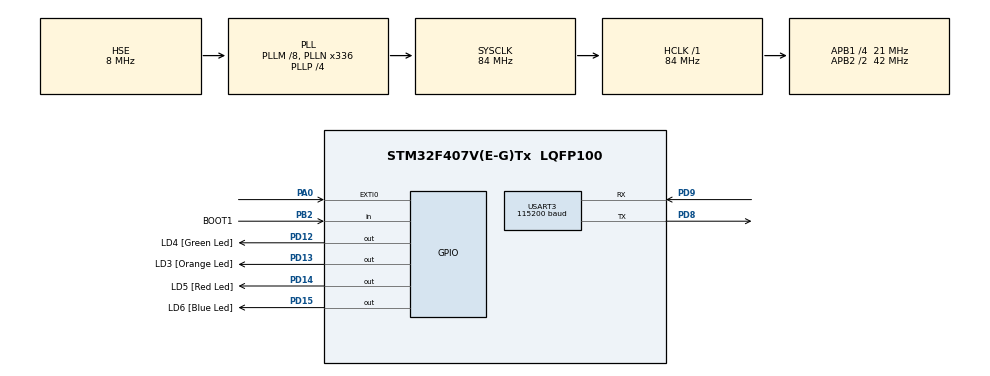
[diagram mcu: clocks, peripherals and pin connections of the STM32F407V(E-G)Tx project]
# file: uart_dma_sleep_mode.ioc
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Dma.Request0=USART3_RX
Dma.Request1=USART3_TX
Dma.USART3_RX.0.Direction=DMA_PERIPH_TO_MEMORY
Dma.USART3_RX.0.FIFOMode=DMA_FIFOMODE_DISABLE
Dma.USART3_RX.0.Instance=DMA1_Stream1
Dma.USART3_RX.0.MemDataAlignment=DMA_MDATAALIGN_BYTE
Dma.USART3_RX.0.MemInc=DMA_MINC_ENABLE
Dma.USART3_RX.0.Mode=DMA_NORMAL
Dma.USART3_RX.0.PeriphDataAlignment=DMA_PDATAALIGN_BYTE
Dma.USART3_RX.0.PeriphInc=DMA_PINC_DISABLE
Dma.USART3_RX.0.Priority=DMA_PRIORITY_LOW
Dma.USART3_TX.1.Direction=DMA_MEMORY_TO_PERIPH
Dma.USART3_TX.1.FIFOMode=DMA_FIFOMODE_ENABLE
Dma.USART3_TX.1.FIFOThreshold=DMA_FIFO_THRESHOLD_FULL
Dma.USART3_TX.1.Instance=DMA1_Stream3
Dma.USART3_TX.1.MemBurst=DMA_MBURST_SINGLE
Dma.USART3_TX.1.MemDataAlignment=DMA_MDATAALIGN_BYTE
Dma.USART3_TX.1.MemInc=DMA_MINC_ENABLE
Dma.USART3_TX.1.Mode=DMA_NORMAL
Dma.USART3_TX.1.PeriphBurst=DMA_PBURST_SINGLE
Dma.USART3_TX.1.PeriphDataAlignment=DMA_PDATAALIGN_BYTE
Dma.USART3_TX.1.PeriphInc=DMA_PINC_DISABLE
Dma.USART3_TX.1.Priority=DMA_PRIORITY_LOW
Mcu.Family=STM32F4
Mcu.Name=STM32F407V(E-G)Tx
Mcu.Package=LQFP100
NVIC.DMA1_Stream1_IRQn=true\:0\:0\:false\:false\:true\:false\:true
NVIC.DMA1_Stream3_IRQn=true\:0\:0\:false\:false\:true\:false\:true
NVIC.EXTI0_IRQn=true\:0\:0\:false\:false\:true\:true\:true
NVIC.PriorityGroup=NVIC_PRIORITYGROUP_0
PA0-WKUP.Signal=GPXTI0
PA13.GPIO_Label=SWDIO
PA13.Mode=Serial_Wire
PA13.Signal=SYS_JTMS-SWDIO
PA14.GPIO_Label=SWCLK
PA14.Mode=Serial_Wire
PA14.Signal=SYS_JTCK-SWCLK
PB2.GPIO_Label=BOOT1
PB2.GPIO_Mode=GPIO_MODE_INPUT
PB2.GPIO_PuPd=GPIO_NOPULL
PB2.Signal=GPIO_Input
PB3.GPIO_Label=SWO
PB3.Signal=SYS_JTDO-SWO
PC14-OSC32_IN.GPIO_Label=PC14-OSC32_IN
PC14-OSC32_IN.Mode=LSE-External-Oscillator
PC14-OSC32_IN.Signal=RCC_OSC32_IN
PC15-OSC32_OUT.GPIO_Label=PC15-OSC32_OUT
PC15-OSC32_OUT.Mode=LSE-External-Oscillator
PC15-OSC32_OUT.Signal=RCC_OSC32_OUT
PD12.GPIO_Label=LD4 [Green Led]
PD12.GPIO_PuPd=GPIO_NOPULL
PD12.GPIO_Speed=GPIO_SPEED_FREQ_LOW
PD12.Signal=GPIO_Output
PD13.GPIO_Label=LD3 [Orange Led]
PD13.GPIO_PuPd=GPIO_NOPULL
PD13.GPIO_Speed=GPIO_SPEED_FREQ_LOW
PD13.Signal=GPIO_Output
PD14.GPIO_Label=LD5 [Red Led]
PD14.GPIO_PuPd=GPIO_NOPULL
PD14.GPIO_Speed=GPIO_SPEED_FREQ_LOW
PD14.Signal=GPIO_Output
PD15.GPIO_Label=LD6 [Blue Led]
PD15.GPIO_PuPd=GPIO_NOPULL
PD15.GPIO_Speed=GPIO_SPEED_FREQ_LOW
PD15.Signal=GPIO_Output
PD8.Mode=Asynchronous
PD8.Signal=USART3_TX
PD9.Mode=Asynchronous
PD9.Signal=USART3_RX
PH0-OSC_IN.GPIO_Label=PH0-OSC_IN
PH0-OSC_IN.Mode=HSE-External-Oscillator
PH0-OSC_IN.Signal=RCC_OSC_IN
PH1-OSC_OUT.GPIO_Label=PH1-OSC_OUT
PH1-OSC_OUT.Mode=HSE-External-Oscillator
PH1-OSC_OUT.Signal=RCC_OSC_OUT
ProjectManager.HeapSize=0x200
ProjectManager.StackSize=0x400
ProjectManager.TargetToolchain=STM32CubeIDE
RCC.48MHZClocksFreq_Value=48000000
RCC.AHBFreq_Value=84000000
RCC.APB1CLKDivider=RCC_HCLK_DIV4
RCC.APB1Freq_Value=21000000
RCC.APB1TimFreq_Value=42000000
RCC.APB2CLKDivider=RCC_HCLK_DIV2
RCC.APB2Freq_Value=42000000
RCC.APB2TimFreq_Value=84000000
RCC.CortexFreq_Value=84000000
RCC.HCLKFreq_Value=84000000
RCC.HSE_VALUE=8000000
RCC.HSI_VALUE=16000000
RCC.PLLM=8
RCC.PLLN=336
RCC.PLLP=RCC_PLLP_DIV4
RCC.PLLQ=7
RCC.PLLSourceVirtual=RCC_PLLSOURCE_HSE
RCC.SYSCLKFreq_VALUE=84000000
RCC.SYSCLKSource=RCC_SYSCLKSOURCE_PLLCLK
RCC.VCOOutputFreq_Value=336000000
USART3.BaudRate=115200
USART3.VirtualMode=VM_ASYNC
board=STM32F407G-DISC1

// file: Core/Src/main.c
/* USER CODE BEGIN Header */
/**
  ******************************************************************************
  * @file           : main.c
  * @brief          : Main program body
  ******************************************************************************
  * @attention
  *
  * <h2><center>&copy; Copyright (c) 2020 STMicroelectronics.
  * All rights reserved.</center></h2>
  *
  * This software component is licensed by ST under Ultimate Liberty license
  * SLA0044, the "License"; You may not use this file except in compliance with
  * the License. You may obtain a copy of the License at:
  *                             www.st.com/SLA0044
  *
  ******************************************************************************
  */
/* USER CODE END Header */
#include "main.h"

UART_HandleTypeDef huart3;
DMA_HandleTypeDef hdma_usart3_rx;
DMA_HandleTypeDef hdma_usart3_tx;

void SystemClock_Config(void);
static void MX_GPIO_Init(void);
static void MX_DMA_Init(void);
static void MX_USART3_UART_Init(void);

int main(void)
{

  /* MCU Configuration--------------------------------------------------------*/

  /* Reset of all peripherals, Initializes the Flash interface and the Systick. */
  HAL_Init();

  /* Configure the system clock */
  SystemClock_Config();

  /* Initialize all configured peripherals */
  MX_GPIO_Init();
  MX_DMA_Init();
  MX_USART3_UART_Init();

  /* Infinite loop */
  while (1)
  {

  }
}

void SystemClock_Config(void)
{
  RCC_OscInitTypeDef RCC_OscInitStruct = {0};
  RCC_ClkInitTypeDef RCC_ClkInitStruct = {0};

  /** Configure the main internal regulator output voltage
  */
  __HAL_RCC_PWR_CLK_ENABLE();
  __HAL_PWR_VOLTAGESCALING_CONFIG(PWR_REGULATOR_VOLTAGE_SCALE1);
  /** Initializes the RCC Oscillators according to the specified parameters
  * in the RCC_OscInitTypeDef structure.
  */
  RCC_OscInitStruct.OscillatorType = RCC_OSCILLATORTYPE_HSE;
  RCC_OscInitStruct.HSEState = RCC_HSE_ON;
  RCC_OscInitStruct.PLL.PLLState = RCC_PLL_ON;
  RCC_OscInitStruct.PLL.PLLSource = RCC_PLLSOURCE_HSE;
  RCC_OscInitStruct.PLL.PLLM = 8;
  RCC_OscInitStruct.PLL.PLLN = 336;
  RCC_OscInitStruct.PLL.PLLP = RCC_PLLP_DIV4;
  RCC_OscInitStruct.PLL.PLLQ = 7;
  if (HAL_RCC_OscConfig(&RCC_OscInitStruct) != HAL_OK)
  {
    Error_Handler();
  }
  /** Initializes the CPU, AHB and APB buses clocks
  */
  RCC_ClkInitStruct.ClockType = RCC_CLOCKTYPE_HCLK|RCC_CLOCKTYPE_SYSCLK
                              |RCC_CLOCKTYPE_PCLK1|RCC_CLOCKTYPE_PCLK2;
  RCC_ClkInitStruct.SYSCLKSource = RCC_SYSCLKSOURCE_PLLCLK;
  RCC_ClkInitStruct.AHBCLKDivider = RCC_SYSCLK_DIV1;
  RCC_ClkInitStruct.APB1CLKDivider = RCC_HCLK_DIV4;
  RCC_ClkInitStruct.APB2CLKDivider = RCC_HCLK_DIV2;

  if (HAL_RCC_ClockConfig(&RCC_ClkInitStruct, FLASH_LATENCY_2) != HAL_OK)
  {
    Error_Handler();
  }
}

static void MX_USART3_UART_Init(void)
{

  huart3.Instance = USART3;
  huart3.Init.BaudRate = 115200;
  huart3.Init.WordLength = UART_WORDLENGTH_8B;
  huart3.Init.StopBits = UART_STOPBITS_1;
  huart3.Init.Parity = UART_PARITY_NONE;
  huart3.Init.Mode = UART_MODE_TX_RX;
  huart3.Init.HwFlowCtl = UART_HWCONTROL_NONE;
  huart3.Init.OverSampling = UART_OVERSAMPLING_16;
  if (HAL_UART_Init(&huart3) != HAL_OK)
  {
    Error_Handler();
  }
  /* USER CODE BEGIN USART3_Init 2 */
  HAL_UART_Transmit_DMA(&huart3, "UART READY\n\r", 15) ;
  /* USER CODE END USART3_Init 2 */

}

static void MX_DMA_Init(void)
{

  /* DMA controller clock enable */
  __HAL_RCC_DMA1_CLK_ENABLE();

  /* DMA interrupt init */
  /* DMA1_Stream1_IRQn interrupt configuration */
  HAL_NVIC_SetPriority(DMA1_Stream1_IRQn, 0, 0);
  HAL_NVIC_EnableIRQ(DMA1_Stream1_IRQn);
  /* DMA1_Stream3_IRQn interrupt configuration */
  HAL_NVIC_SetPriority(DMA1_Stream3_IRQn, 0, 0);
  HAL_NVIC_EnableIRQ(DMA1_Stream3_IRQn);

}

static void MX_GPIO_Init(void)
{
  GPIO_InitTypeDef GPIO_InitStruct = {0};

  /* GPIO Ports Clock Enable */
  __HAL_RCC_GPIOC_CLK_ENABLE();
  __HAL_RCC_GPIOH_CLK_ENABLE();
  __HAL_RCC_GPIOA_CLK_ENABLE();
  __HAL_RCC_GPIOB_CLK_ENABLE();
  __HAL_RCC_GPIOD_CLK_ENABLE();

  /*Configure GPIO pin Output Level */
  HAL_GPIO_WritePin(GPIOD, LD4_Pin|LD3_Pin|LD5_Pin|LD6_Pin, GPIO_PIN_RESET);

  /*Configure GPIO pin : PA0 */
  GPIO_InitStruct.Pin = GPIO_PIN_0;
  GPIO_InitStruct.Mode = GPIO_MODE_IT_RISING;
  GPIO_InitStruct.Pull = GPIO_NOPULL;
  HAL_GPIO_Init(GPIOA, &GPIO_InitStruct);

  /*Configure GPIO pin : BOOT1_Pin */
  GPIO_InitStruct.Pin = BOOT1_Pin;
  GPIO_InitStruct.Mode = GPIO_MODE_INPUT;
  GPIO_InitStruct.Pull = GPIO_NOPULL;
  HAL_GPIO_Init(BOOT1_GPIO_Port, &GPIO_InitStruct);

  /*Configure GPIO pins : LD4_Pin LD3_Pin LD5_Pin LD6_Pin */
  GPIO_InitStruct.Pin = LD4_Pin|LD3_Pin|LD5_Pin|LD6_Pin;
  GPIO_InitStruct.Mode = GPIO_MODE_OUTPUT_PP;
  GPIO_InitStruct.Pull = GPIO_NOPULL;
  GPIO_InitStruct.Speed = GPIO_SPEED_FREQ_LOW;
  HAL_GPIO_Init(GPIOD, &GPIO_InitStruct);

  /* EXTI interrupt init*/
  HAL_NVIC_SetPriority(EXTI0_IRQn, 0, 0);
  HAL_NVIC_EnableIRQ(EXTI0_IRQn);

}

void Error_Handler(void)
{
}

/************************ (C) COPYRIGHT STMicroelectronics *****END OF FILE****/
